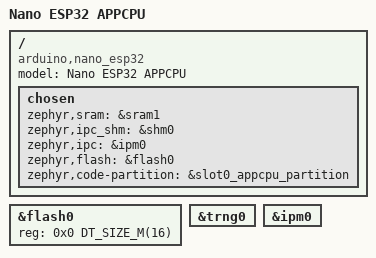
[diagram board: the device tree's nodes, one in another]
/*
 * Copyright (c) 2025 Arduino SA
 *
 * SPDX-License-Identifier: Apache-2.0
 */
/dts-v1/;

#include <espressif/esp32s3/esp32s3_r8.dtsi>
#include "arduino_nano_esp32-partitions.dtsi"
#include "arduino_nano_esp32-pinctrl.dtsi"

/ {
	model = "Nano ESP32 APPCPU";
	compatible = "arduino,nano_esp32";

	chosen {
		zephyr,sram = &sram1;
		zephyr,ipc_shm = &shm0;
		zephyr,ipc = &ipm0;
		zephyr,flash = &flash0;
		zephyr,code-partition = &slot0_appcpu_partition;
	};
};

/* 16MB flash */
&flash0 {
	reg = <0x0 DT_SIZE_M(16)>;
};

&trng0 {
	status = "okay";
};

&ipm0 {
	status = "okay";
};
